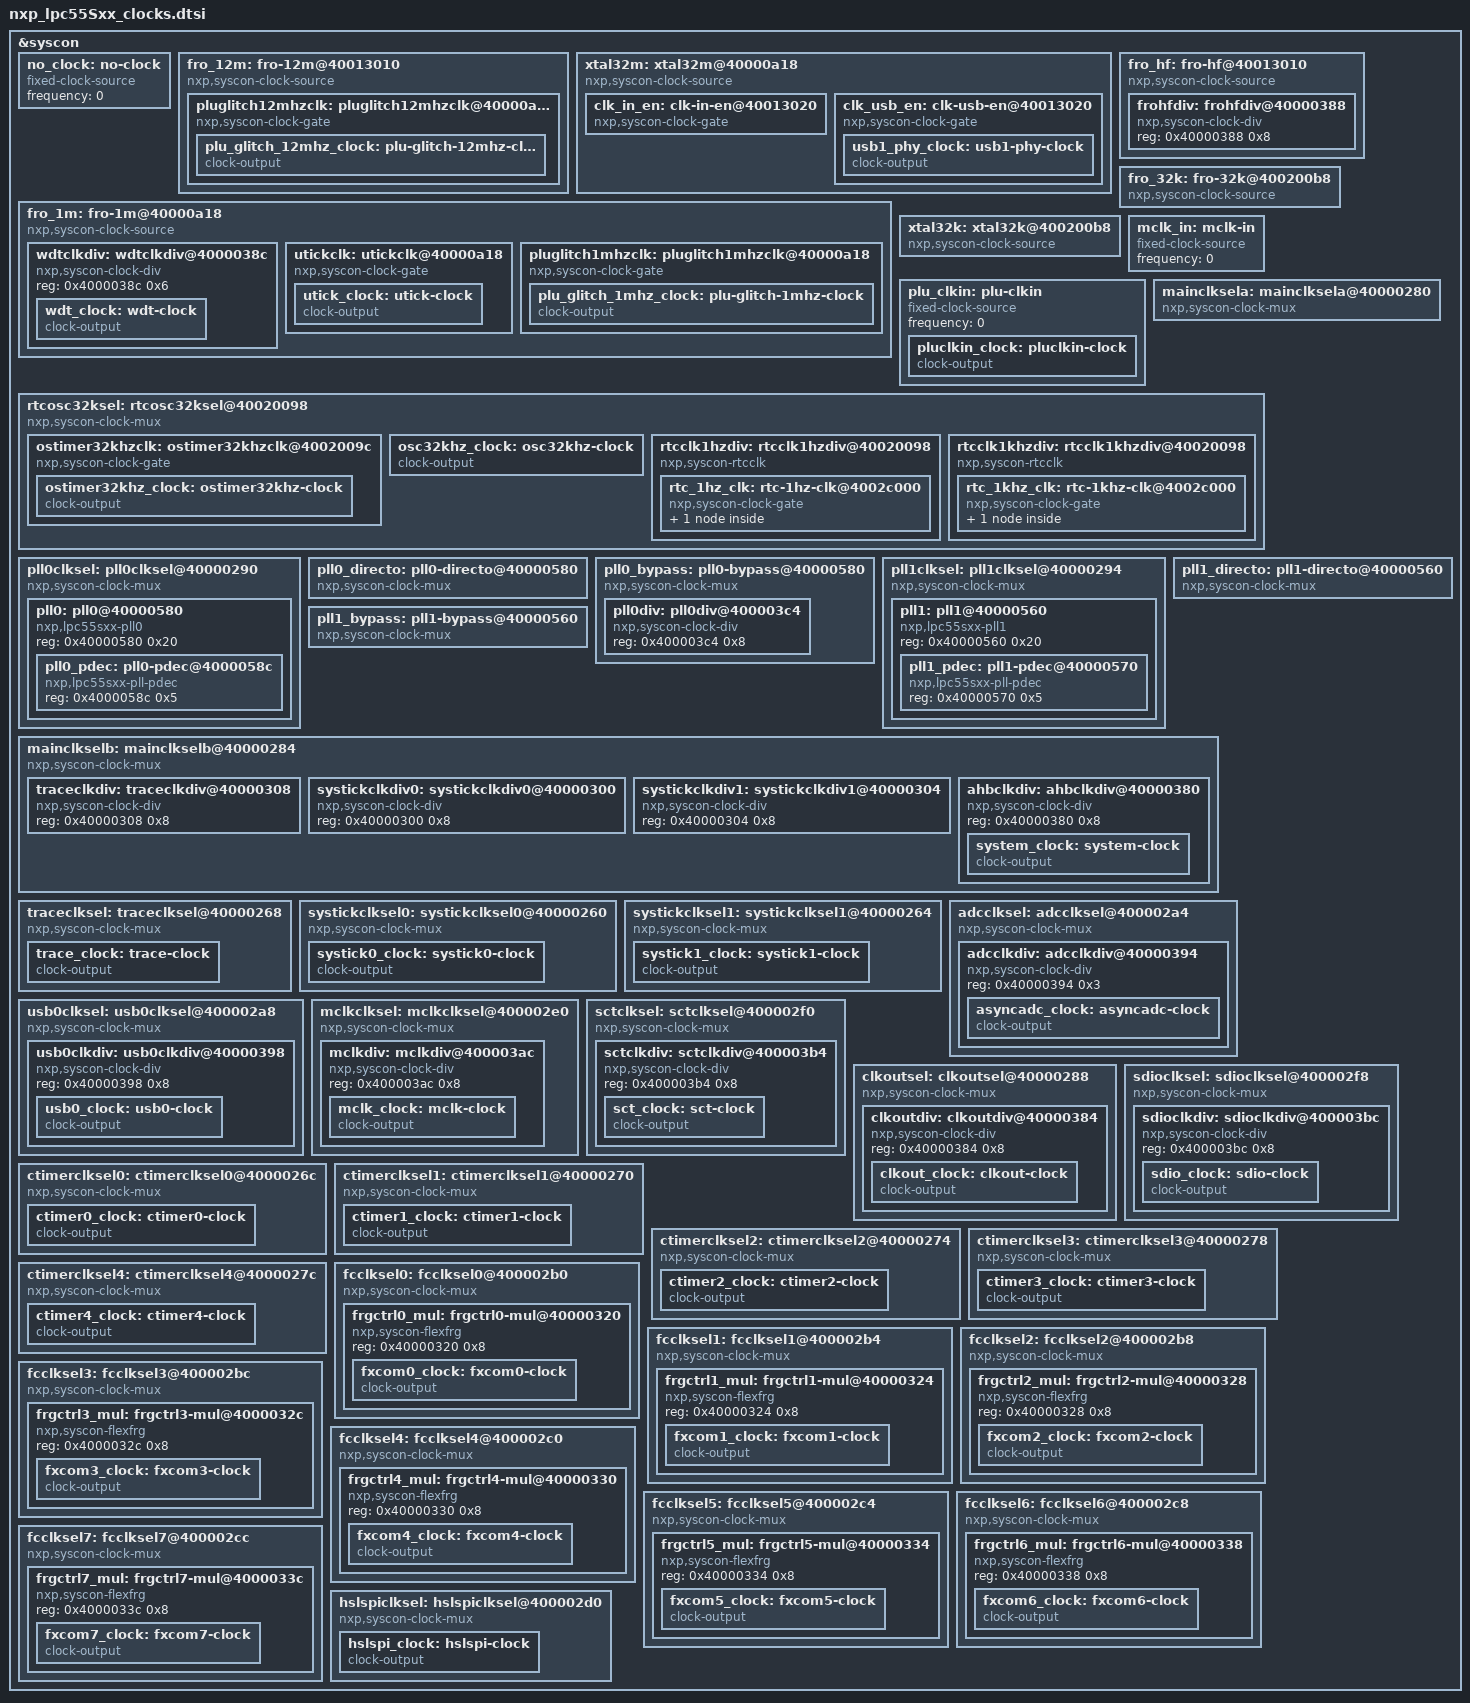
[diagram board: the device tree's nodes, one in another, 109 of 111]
/*
 * Copyright 2024 NXP
 *
 * SPDX-License-Identifier: Apache-2.0
 */

/* Generated from NXP MCUX clock data */
&syscon {
	#address-cells = <1>;
	#size-cells = <1>;

	/* Root clock sources */
	no_clock: no-clock {
		/* Dummy node- indicates no clock source was selected */
		compatible = "fixed-clock-source";
		#clock-cells = <0>;
		frequency = <0>;
	};

	fro_12m: fro-12m@40013010 {
		compatible = "nxp,syscon-clock-source";
		offset = <0xe>;
		#clock-cells = <1>;
		/* ANACTRL::FRO192M_CTRL[ENA_12MHZCLK] */
		reg = <0x40013010 0x1>;
		frequency = <12000000>;
		#address-cells = <1>;
		#size-cells = <1>;

		pluglitch12mhzclk: pluglitch12mhzclk@40000a18 {
			compatible = "nxp,syscon-clock-gate";
			#clock-cells = <1>;
			/* SYSCON::CLOCK_CTRL[PLU_DEGLITCH_CLK_ENA] */
			reg = <0x40000a18 0x1>;
			offset = <0x9>;

			plu_glitch_12mhz_clock: plu-glitch-12mhz-clock {
				compatible = "clock-output";
				#clock-cells = <1>;
			};
		};
	};

	xtal32m: xtal32m@40000a18 {
		compatible = "nxp,syscon-clock-source";
		offset = <0x5>;
		#clock-cells = <1>;
		/* PMC::PDRUNCFG0[PDEN_LDOXO32M | PDEN_XTAL32M] */
		pdown-mask = <0x100100>;
		/* SYSCON::CLOCK_CTRL[CLKIN_ENA] */
		reg = <0x40000a18 0x1>;
		/* External clock source (default 16 MHz) */
		frequency = <16000000>;
		#address-cells = <1>;
		#size-cells = <1>;

		clk_in_en: clk-in-en@40013020 {
			compatible = "nxp,syscon-clock-gate";
			#clock-cells = <1>;
			/* ANACTRL::XO32M_CTRL[ENABLE_SYSTEM_CLK_OUT] */
			reg = <0x40013020 0x1>;
			offset = <0x18>;
		};

		clk_usb_en: clk-usb-en@40013020 {
			compatible = "nxp,syscon-clock-gate";
			#clock-cells = <1>;
			/* ANACTRL::XO32M_CTRL[ENABLE_PLL_USB_OUT] */
			reg = <0x40013020 0x1>;
			offset = <0x17>;

			usb1_phy_clock: usb1-phy-clock {
				compatible = "clock-output";
				#clock-cells = <1>;
			};
		};
	};

	fro_1m: fro-1m@40000a18 {
		compatible = "nxp,syscon-clock-source";
		offset = <0x6>;
		#clock-cells = <1>;
		/* SYSCON::CLOCK_CTRL[FRO1MHZ_CLK_ENA] */
		reg = <0x40000a18 0x1>;
		frequency = <1000000>;
		#address-cells = <1>;
		#size-cells = <1>;

		wdtclkdiv: wdtclkdiv@4000038c {
			compatible = "nxp,syscon-clock-div";
			#clock-cells = <1>;
			/* SYSCON::WDTCLKDIV[DIV] */
			reg = <0x4000038c 0x6>;

			wdt_clock: wdt-clock {
				compatible = "clock-output";
				#clock-cells = <1>;
			};
		};

		utickclk: utickclk@40000a18 {
			compatible = "nxp,syscon-clock-gate";
			#clock-cells = <1>;
			/* SYSCON::CLOCK_CTRL[FRO1MHZ_UTICK_ENA] */
			reg = <0x40000a18 0x1>;
			offset = <0x2>;

			utick_clock: utick-clock {
				compatible = "clock-output";
				#clock-cells = <1>;
			};
		};

		pluglitch1mhzclk: pluglitch1mhzclk@40000a18 {
			compatible = "nxp,syscon-clock-gate";
			#clock-cells = <1>;
			/* SYSCON::CLOCK_CTRL[PLU_DEGLITCH_CLK_ENA] */
			reg = <0x40000a18 0x1>;
			offset = <0x9>;

			plu_glitch_1mhz_clock: plu-glitch-1mhz-clock {
				compatible = "clock-output";
				#clock-cells = <1>;
			};
		};
	};

	fro_hf: fro-hf@40013010 {
		compatible = "nxp,syscon-clock-source";
		offset = <0x1e>;
		#clock-cells = <1>;
		/* ANACTRL::FRO192M_CTRL[ENA_96MHZCLK] */
		reg = <0x40013010 0x1>;
		frequency = <96000000>;
		#address-cells = <1>;
		#size-cells = <1>;

		frohfdiv: frohfdiv@40000388 {
			compatible = "nxp,syscon-clock-div";
			#clock-cells = <1>;
			/* SYSCON::FROHFDIV[DIV] */
			reg = <0x40000388 0x8>;
		};
	};

	fro_32k: fro-32k@400200b8 {
		compatible = "nxp,syscon-clock-source";
		offset = <0x6>;
		#clock-cells = <1>;
		/* PMC::PDRUNCFG0[PDEN_FRO32K] */
		pdown-mask = <0x40>;
		/* PMC::PDRUNCFG0[PDEN_FRO32K] */
		reg = <0x400200b8 0x1>;
		frequency = <32768>;
	};

	xtal32k: xtal32k@400200b8 {
		compatible = "nxp,syscon-clock-source";
		offset = <0x7>;
		#clock-cells = <1>;
		/* PMC::PDRUNCFG0[PDEN_XTAL32K] */
		pdown-mask = <0x80>;
		/* PMC::PDRUNCFG0[PDEN_XTAL32K] */
		reg = <0x400200b8 0x1>;
		/* External clock source (default 32768 Hz) */
		frequency = <32768>;
	};

	mclk_in: mclk-in {
		compatible = "fixed-clock-source";
		#clock-cells = <0>;
		/* External clock source */
		frequency = <0>;
	};

	plu_clkin: plu-clkin {
		compatible = "fixed-clock-source";
		#clock-cells = <0>;
		/* External clock source */
		frequency = <0>;

		pluclkin_clock: pluclkin-clock {
			compatible = "clock-output";
			#clock-cells = <1>;
		};
	};

	/* Clock muxes */
	mainclksela: mainclksela@40000280 {
		compatible = "nxp,syscon-clock-mux";
		#clock-cells = <1>;
		/* SYSCON::MAINCLKSELA[SEL] */
		reg = <0x40000280 0x3>;
		offset = <0x0>;
		safe-mux;
		input-sources = <&fro_12m &clk_in_en &fro_1m &fro_hf>;
	};

	rtcosc32ksel: rtcosc32ksel@40020098 {
		compatible = "nxp,syscon-clock-mux";
		#clock-cells = <1>;
		/* PMC::RTCOSC32K[SEL] */
		reg = <0x40020098 0x1>;
		offset = <0x0>;
		input-sources = <&fro_32k &xtal32k>;
		#address-cells = <1>;
		#size-cells = <1>;

		ostimer32khzclk: ostimer32khzclk@4002009c {
			compatible = "nxp,syscon-clock-gate";
			#clock-cells = <1>;
			/* PMC::OSTIMER[CLOCKENABLE] */
			reg = <0x4002009c 0x1>;
			offset = <0x1>;

			ostimer32khz_clock: ostimer32khz-clock {
				compatible = "clock-output";
				#clock-cells = <1>;
			};
		};

		osc32khz_clock: osc32khz-clock {
			compatible = "clock-output";
			#clock-cells = <1>;
		};

		rtcclk1hzdiv: rtcclk1hzdiv@40020098 {
			compatible = "nxp,syscon-rtcclk";
			#clock-cells = <1>;
			/* PMC::RTCOSC32K[CLK1HZDIV] */
			reg = <0x40020098 0xb>;
			offset = <0x10>;
			add-factor = <31744>;
			#address-cells = <1>;
			#size-cells = <1>;

			rtc_1hz_clk: rtc-1hz-clk@4002c000 {
				compatible = "nxp,syscon-clock-gate";
				#clock-cells = <1>;
				/* RTC::CTRL[RTC_EN] */
				reg = <0x4002c000 0x1>;
				offset = <0x7>;

				rtc1hz_clock: rtc1hz-clock {
					compatible = "clock-output";
					#clock-cells = <1>;
				};
			};
		};

		rtcclk1khzdiv: rtcclk1khzdiv@40020098 {
			compatible = "nxp,syscon-rtcclk";
			#clock-cells = <1>;
			/* PMC::RTCOSC32K[CLK1KHZDIV] */
			reg = <0x40020098 0x3>;
			offset = <0x1>;
			add-factor = <28>;
			#address-cells = <1>;
			#size-cells = <1>;

			rtc_1khz_clk: rtc-1khz-clk@4002c000 {
				compatible = "nxp,syscon-clock-gate";
				#clock-cells = <1>;
				/* RTC::CTRL[RTC1KHZ_EN] */
				reg = <0x4002c000 0x1>;
				offset = <0x6>;

				rtc1khz_clock: rtc1khz-clock {
					compatible = "clock-output";
					#clock-cells = <1>;
				};
			};
		};
	};

	pll0clksel: pll0clksel@40000290 {
		compatible = "nxp,syscon-clock-mux";
		#clock-cells = <1>;
		/* SYSCON::PLL0CLKSEL[SEL] */
		reg = <0x40000290 0x3>;
		offset = <0x0>;
		input-sources = <&fro_12m &clk_in_en &fro_1m &rtcosc32ksel
				&no_clock>;
		#address-cells = <1>;
		#size-cells = <1>;

		pll0: pll0@40000580 {
			compatible = "nxp,lpc55sxx-pll0";
			reg = <0x40000580 0x20>;
			#clock-cells = <9>;
			#address-cells = <1>;
			#size-cells = <1>;

			pll0_pdec: pll0-pdec@4000058c {
				compatible = "nxp,lpc55sxx-pll-pdec";
				/* SYSCON::PLL0PDEC[PDIV] */
				reg = <0x4000058c 0x5>;
				#clock-cells = <1>;
			};
		};
	};

	pll0_directo: pll0-directo@40000580 {
		compatible = "nxp,syscon-clock-mux";
		#clock-cells = <1>;
		/* SYSCON::PLL0CTRL[BYPASSPOSTDIV] */
		reg = <0x40000580 0x1>;
		offset = <0x14>;
		input-sources = <&pll0_pdec &pll0>;
	};

	pll0_bypass: pll0-bypass@40000580 {
		compatible = "nxp,syscon-clock-mux";
		#clock-cells = <1>;
		/* SYSCON::PLL0CTRL[BYPASSPLL] */
		reg = <0x40000580 0x1>;
		offset = <0xf>;
		input-sources = <&pll0_directo &pll0clksel>;
		#address-cells = <1>;
		#size-cells = <1>;

		pll0div: pll0div@400003c4 {
			compatible = "nxp,syscon-clock-div";
			#clock-cells = <1>;
			/* SYSCON::PLL0CLKDIV[DIV] */
			reg = <0x400003c4 0x8>;
		};
	};

	pll1clksel: pll1clksel@40000294 {
		compatible = "nxp,syscon-clock-mux";
		#clock-cells = <1>;
		/* SYSCON::PLL1CLKSEL[SEL] */
		reg = <0x40000294 0x3>;
		offset = <0x0>;
		input-sources = <&fro_12m &clk_in_en &fro_1m &rtcosc32ksel
				&no_clock>;
		#address-cells = <1>;
		#size-cells = <1>;

		pll1: pll1@40000560 {
			compatible = "nxp,lpc55sxx-pll1";
			reg = <0x40000560 0x20>;
			#clock-cells = <6>;
			#address-cells = <1>;
			#size-cells = <1>;

			pll1_pdec: pll1-pdec@40000570 {
				compatible = "nxp,lpc55sxx-pll-pdec";
				/* SYSCON::PLL1PDEC[PDIV] */
				reg = <0x40000570 0x5>;
				#clock-cells = <1>;
			};
		};
	};

	pll1_directo: pll1-directo@40000560 {
		compatible = "nxp,syscon-clock-mux";
		#clock-cells = <1>;
		/* SYSCON::PLL1CTRL[BYPASSPOSTDIV] */
		reg = <0x40000560 0x1>;
		offset = <0x14>;
		input-sources = <&pll1_pdec &pll1>;
	};

	pll1_bypass: pll1-bypass@40000560 {
		compatible = "nxp,syscon-clock-mux";
		#clock-cells = <1>;
		/* SYSCON::PLL1CTRL[BYPASSPLL] */
		reg = <0x40000560 0x1>;
		offset = <0xf>;
		input-sources = <&pll1_directo &pll1clksel>;
	};

	mainclkselb: mainclkselb@40000284 {
		compatible = "nxp,syscon-clock-mux";
		#clock-cells = <1>;
		/* SYSCON::MAINCLKSELB[SEL] */
		reg = <0x40000284 0x3>;
		offset = <0x0>;
		safe-mux;
		input-sources = <&mainclksela &pll0_bypass &pll1_bypass &rtcosc32ksel>;
		#address-cells = <1>;
		#size-cells = <1>;

		traceclkdiv: traceclkdiv@40000308 {
			compatible = "nxp,syscon-clock-div";
			#clock-cells = <1>;
			/* SYSCON::TRACECLKDIV[DIV] */
			reg = <0x40000308 0x8>;
		};

		systickclkdiv0: systickclkdiv0@40000300 {
			compatible = "nxp,syscon-clock-div";
			#clock-cells = <1>;
			/* SYSCON::SYSTICKCLKDIV0[DIV] */
			reg = <0x40000300 0x8>;
		};

		systickclkdiv1: systickclkdiv1@40000304 {
			compatible = "nxp,syscon-clock-div";
			#clock-cells = <1>;
			/* SYSCON::SYSTICKCLKDIV1[DIV] */
			reg = <0x40000304 0x8>;
		};

		ahbclkdiv: ahbclkdiv@40000380 {
			compatible = "nxp,syscon-clock-div";
			#clock-cells = <1>;
			/* SYSCON::AHBCLKDIV[DIV] */
			reg = <0x40000380 0x8>;

			system_clock: system-clock {
				compatible = "clock-output";
				#clock-cells = <1>;
			};
		};
	};

	traceclksel: traceclksel@40000268 {
		compatible = "nxp,syscon-clock-mux";
		#clock-cells = <1>;
		/* SYSCON::TRACECLKSEL[SEL] */
		reg = <0x40000268 0x3>;
		offset = <0x0>;
		input-sources = <&traceclkdiv &fro_1m &rtcosc32ksel &no_clock>;

		trace_clock: trace-clock {
			compatible = "clock-output";
			#clock-cells = <1>;
		};
	};

	systickclksel0: systickclksel0@40000260 {
		compatible = "nxp,syscon-clock-mux";
		#clock-cells = <1>;
		/* SYSCON::SYSTICKCLKSEL0[SEL] */
		reg = <0x40000260 0x3>;
		offset = <0x0>;
		input-sources = <&systickclkdiv0 &fro_1m &rtcosc32ksel &no_clock>;

		systick0_clock: systick0-clock {
			compatible = "clock-output";
			#clock-cells = <1>;
		};
	};

	systickclksel1: systickclksel1@40000264 {
		compatible = "nxp,syscon-clock-mux";
		#clock-cells = <1>;
		/* SYSCON::SYSTICKCLKSEL1[SEL] */
		reg = <0x40000264 0x3>;
		offset = <0x0>;
		input-sources = <&systickclkdiv1 &fro_1m &rtcosc32ksel &no_clock>;

		systick1_clock: systick1-clock {
			compatible = "clock-output";
			#clock-cells = <1>;
		};
	};

	adcclksel: adcclksel@400002a4 {
		compatible = "nxp,syscon-clock-mux";
		#clock-cells = <1>;
		/* SYSCON::ADCCLKSEL[SEL] */
		reg = <0x400002a4 0x3>;
		offset = <0x0>;
		input-sources = <&mainclkselb &pll0_bypass &fro_hf &no_clock>;
		#address-cells = <1>;
		#size-cells = <1>;

		adcclkdiv: adcclkdiv@40000394 {
			compatible = "nxp,syscon-clock-div";
			#clock-cells = <1>;
			/* SYSCON::ADCCLKDIV[DIV] */
			reg = <0x40000394 0x3>;

			asyncadc_clock: asyncadc-clock {
				compatible = "clock-output";
				#clock-cells = <1>;
			};
		};
	};

	usb0clksel: usb0clksel@400002a8 {
		compatible = "nxp,syscon-clock-mux";
		#clock-cells = <1>;
		/* SYSCON::USB0CLKSEL[SEL] */
		reg = <0x400002a8 0x3>;
		offset = <0x0>;
		input-sources = <&mainclkselb &pll0_bypass &no_clock &fro_hf
				&no_clock &pll1_bypass &no_clock>;
		#address-cells = <1>;
		#size-cells = <1>;

		usb0clkdiv: usb0clkdiv@40000398 {
			compatible = "nxp,syscon-clock-div";
			#clock-cells = <1>;
			/* SYSCON::USB0CLKDIV[DIV] */
			reg = <0x40000398 0x8>;

			usb0_clock: usb0-clock {
				compatible = "clock-output";
				#clock-cells = <1>;
			};
		};
	};

	mclkclksel: mclkclksel@400002e0 {
		compatible = "nxp,syscon-clock-mux";
		#clock-cells = <1>;
		/* SYSCON::MCLKCLKSEL[SEL] */
		reg = <0x400002e0 0x3>;
		offset = <0x0>;
		input-sources = <&fro_hf &pll0_bypass &no_clock>;
		#address-cells = <1>;
		#size-cells = <1>;

		mclkdiv: mclkdiv@400003ac {
			compatible = "nxp,syscon-clock-div";
			#clock-cells = <1>;
			/* SYSCON::MCLKDIV[DIV] */
			reg = <0x400003ac 0x8>;

			mclk_clock: mclk-clock {
				compatible = "clock-output";
				#clock-cells = <1>;
			};
		};
	};

	sctclksel: sctclksel@400002f0 {
		compatible = "nxp,syscon-clock-mux";
		#clock-cells = <1>;
		/* SYSCON::SCTCLKSEL[SEL] */
		reg = <0x400002f0 0x3>;
		offset = <0x0>;
		input-sources = <&mainclkselb &pll0_bypass &clk_in_en &fro_hf
				&no_clock &mclk_in &no_clock>;
		#address-cells = <1>;
		#size-cells = <1>;

		sctclkdiv: sctclkdiv@400003b4 {
			compatible = "nxp,syscon-clock-div";
			#clock-cells = <1>;
			/* SYSCON::SCTCLKDIV[DIV] */
			reg = <0x400003b4 0x8>;

			sct_clock: sct-clock {
				compatible = "clock-output";
				#clock-cells = <1>;
			};
		};
	};

	clkoutsel: clkoutsel@40000288 {
		compatible = "nxp,syscon-clock-mux";
		#clock-cells = <1>;
		/* SYSCON::CLKOUTSEL[SEL] */
		reg = <0x40000288 0x3>;
		offset = <0x0>;
		input-sources = <&mainclkselb &pll0_bypass &clk_in_en &fro_hf
				&fro_1m &pll1_bypass &rtcosc32ksel &no_clock>;
		#address-cells = <1>;
		#size-cells = <1>;

		clkoutdiv: clkoutdiv@40000384 {
			compatible = "nxp,syscon-clock-div";
			#clock-cells = <1>;
			/* SYSCON::CLKOUTDIV[DIV] */
			reg = <0x40000384 0x8>;

			clkout_clock: clkout-clock {
				compatible = "clock-output";
				#clock-cells = <1>;
			};
		};
	};

	sdioclksel: sdioclksel@400002f8 {
		compatible = "nxp,syscon-clock-mux";
		#clock-cells = <1>;
		/* SYSCON::SDIOCLKSEL[SEL] */
		reg = <0x400002f8 0x3>;
		offset = <0x0>;
		input-sources = <&mainclkselb &pll0_bypass &no_clock &fro_hf
				&no_clock &pll1_bypass &no_clock>;
		#address-cells = <1>;
		#size-cells = <1>;

		sdioclkdiv: sdioclkdiv@400003bc {
			compatible = "nxp,syscon-clock-div";
			#clock-cells = <1>;
			/* SYSCON::SDIOCLKDIV[DIV] */
			reg = <0x400003bc 0x8>;

			sdio_clock: sdio-clock {
				compatible = "clock-output";
				#clock-cells = <1>;
			};
		};
	};

	ctimerclksel0: ctimerclksel0@4000026c {
		compatible = "nxp,syscon-clock-mux";
		#clock-cells = <1>;
		/* SYSCON::CTIMERCLKSEL0[SEL] */
		reg = <0x4000026c 0x3>;
		offset = <0x0>;
		input-sources = <&mainclkselb &pll0_bypass &no_clock &fro_hf
				&fro_1m &mclk_in &rtcosc32ksel &no_clock>;

		ctimer0_clock: ctimer0-clock {
			compatible = "clock-output";
			#clock-cells = <1>;
		};
	};

	ctimerclksel1: ctimerclksel1@40000270 {
		compatible = "nxp,syscon-clock-mux";
		#clock-cells = <1>;
		/* SYSCON::CTIMERCLKSEL1[SEL] */
		reg = <0x40000270 0x3>;
		offset = <0x0>;
		input-sources = <&mainclkselb &pll0_bypass &no_clock &fro_hf
				&fro_1m &mclk_in &rtcosc32ksel &no_clock>;

		ctimer1_clock: ctimer1-clock {
			compatible = "clock-output";
			#clock-cells = <1>;
		};
	};

	ctimerclksel2: ctimerclksel2@40000274 {
		compatible = "nxp,syscon-clock-mux";
		#clock-cells = <1>;
		/* SYSCON::CTIMERCLKSEL2[SEL] */
		reg = <0x40000274 0x3>;
		offset = <0x0>;
		input-sources = <&mainclkselb &pll0_bypass &no_clock &fro_hf
				&fro_1m &mclk_in &rtcosc32ksel &no_clock>;

		ctimer2_clock: ctimer2-clock {
			compatible = "clock-output";
			#clock-cells = <1>;
		};
	};

	ctimerclksel3: ctimerclksel3@40000278 {
		compatible = "nxp,syscon-clock-mux";
		#clock-cells = <1>;
		/* SYSCON::CTIMERCLKSEL3[SEL] */
		reg = <0x40000278 0x3>;
		offset = <0x0>;
		input-sources = <&mainclkselb &pll0_bypass &no_clock &fro_hf
				&fro_1m &mclk_in &rtcosc32ksel &no_clock>;

		ctimer3_clock: ctimer3-clock {
			compatible = "clock-output";
			#clock-cells = <1>;
		};
	};

	ctimerclksel4: ctimerclksel4@4000027c {
		compatible = "nxp,syscon-clock-mux";
		#clock-cells = <1>;
		/* SYSCON::CTIMERCLKSEL4[SEL] */
		reg = <0x4000027c 0x3>;
		offset = <0x0>;
		input-sources = <&mainclkselb &pll0_bypass &no_clock &fro_hf
				&fro_1m &mclk_in &rtcosc32ksel &no_clock>;

		ctimer4_clock: ctimer4-clock {
			compatible = "clock-output";
			#clock-cells = <1>;
		};
	};

	fcclksel0: fcclksel0@400002b0 {
		compatible = "nxp,syscon-clock-mux";
		#clock-cells = <1>;
		/* SYSCON::FCCLKSEL0[SEL] */
		reg = <0x400002b0 0x3>;
		offset = <0x0>;
		input-sources = <&mainclkselb &pll0div &fro_12m &frohfdiv &fro_1m
				&mclk_in &rtcosc32ksel &no_clock>;
		#address-cells = <1>;
		#size-cells = <1>;

		frgctrl0_mul: frgctrl0-mul@40000320 {
			compatible = "nxp,syscon-flexfrg";
			#clock-cells = <1>;
			/* SYSCON::FLEXFRG0CTRL[MULT] */
			reg = <0x40000320 0x8>;

			fxcom0_clock: fxcom0-clock {
				compatible = "clock-output";
				#clock-cells = <1>;
			};
		};
	};

	fcclksel1: fcclksel1@400002b4 {
		compatible = "nxp,syscon-clock-mux";
		#clock-cells = <1>;
		/* SYSCON::FCCLKSEL1[SEL] */
		reg = <0x400002b4 0x3>;
		offset = <0x0>;
		input-sources = <&mainclkselb &pll0div &fro_12m &frohfdiv &fro_1m
				&mclk_in &rtcosc32ksel &no_clock>;
		#address-cells = <1>;
		#size-cells = <1>;

		frgctrl1_mul: frgctrl1-mul@40000324 {
			compatible = "nxp,syscon-flexfrg";
			#clock-cells = <1>;
			/* SYSCON::FLEXFRG1CTRL[MULT] */
			reg = <0x40000324 0x8>;

			fxcom1_clock: fxcom1-clock {
				compatible = "clock-output";
				#clock-cells = <1>;
			};
		};
	};

	fcclksel2: fcclksel2@400002b8 {
		compatible = "nxp,syscon-clock-mux";
		#clock-cells = <1>;
		/* SYSCON::FCCLKSEL2[SEL] */
		reg = <0x400002b8 0x3>;
		offset = <0x0>;
		input-sources = <&mainclkselb &pll0div &fro_12m &frohfdiv &fro_1m
				&mclk_in &rtcosc32ksel &no_clock>;
		#address-cells = <1>;
		#size-cells = <1>;

		frgctrl2_mul: frgctrl2-mul@40000328 {
			compatible = "nxp,syscon-flexfrg";
			#clock-cells = <1>;
			/* SYSCON::FLEXFRG2CTRL[MULT] */
			reg = <0x40000328 0x8>;

			fxcom2_clock: fxcom2-clock {
				compatible = "clock-output";
				#clock-cells = <1>;
			};
		};
	};

	fcclksel3: fcclksel3@400002bc {
		compatible = "nxp,syscon-clock-mux";
		#clock-cells = <1>;
		/* SYSCON::FCCLKSEL3[SEL] */
		reg = <0x400002bc 0x3>;
		offset = <0x0>;
		input-sources = <&mainclkselb &pll0div &fro_12m &frohfdiv &fro_1m
				&mclk_in &rtcosc32ksel &no_clock>;
		#address-cells = <1>;
		#size-cells = <1>;

		frgctrl3_mul: frgctrl3-mul@4000032c {
			compatible = "nxp,syscon-flexfrg";
			#clock-cells = <1>;
			/* SYSCON::FLEXFRG3CTRL[MULT] */
			reg = <0x4000032c 0x8>;

			fxcom3_clock: fxcom3-clock {
				compatible = "clock-output";
				#clock-cells = <1>;
			};
		};
	};

	fcclksel4: fcclksel4@400002c0 {
		compatible = "nxp,syscon-clock-mux";
		#clock-cells = <1>;
		/* SYSCON::FCCLKSEL4[SEL] */
		reg = <0x400002c0 0x3>;
		offset = <0x0>;
		input-sources = <&mainclkselb &pll0div &fro_12m &frohfdiv &fro_1m
				&mclk_in &rtcosc32ksel &no_clock>;
		#address-cells = <1>;
		#size-cells = <1>;

		frgctrl4_mul: frgctrl4-mul@40000330 {
			compatible = "nxp,syscon-flexfrg";
			#clock-cells = <1>;
			/* SYSCON::FLEXFRG4CTRL[MULT] */
			reg = <0x40000330 0x8>;

			fxcom4_clock: fxcom4-clock {
				compatible = "clock-output";
				#clock-cells = <1>;
			};
		};
	};

	fcclksel5: fcclksel5@400002c4 {
		compatible = "nxp,syscon-clock-mux";
		#clock-cells = <1>;
		/* SYSCON::FCCLKSEL5[SEL] */
		reg = <0x400002c4 0x3>;
		offset = <0x0>;
		input-sources = <&mainclkselb &pll0div &fro_12m &frohfdiv &fro_1m
				&mclk_in &rtcosc32ksel &no_clock>;
		#address-cells = <1>;
		#size-cells = <1>;

		frgctrl5_mul: frgctrl5-mul@40000334 {
			compatible = "nxp,syscon-flexfrg";
			#clock-cells = <1>;
			/* SYSCON::FLEXFRG5CTRL[MULT] */
			reg = <0x40000334 0x8>;

			fxcom5_clock: fxcom5-clock {
				compatible = "clock-output";
				#clock-cells = <1>;
			};
		};
	};

	fcclksel6: fcclksel6@400002c8 {
		compatible = "nxp,syscon-clock-mux";
		#clock-cells = <1>;
		/* SYSCON::FCCLKSEL6[SEL] */
		reg = <0x400002c8 0x3>;
		offset = <0x0>;
		input-sources = <&mainclkselb &pll0div &fro_12m &frohfdiv &fro_1m
				&mclk_in &rtcosc32ksel &no_clock>;
		#address-cells = <1>;
		#size-cells = <1>;

		frgctrl6_mul: frgctrl6-mul@40000338 {
			compatible = "nxp,syscon-flexfrg";
			#clock-cells = <1>;
			/* SYSCON::FLEXFRG6CTRL[MULT] */
			reg = <0x40000338 0x8>;

			fxcom6_clock: fxcom6-clock {
				compatible = "clock-output";
				#clock-cells = <1>;
			};
		};
	};

	fcclksel7: fcclksel7@400002cc {
		compatible = "nxp,syscon-clock-mux";
		#clock-cells = <1>;
		/* SYSCON::FCCLKSEL7[SEL] */
		reg = <0x400002cc 0x3>;
		offset = <0x0>;
		input-sources = <&mainclkselb &pll0div &fro_12m &frohfdiv &fro_1m
				&mclk_in &rtcosc32ksel &no_clock>;
		#address-cells = <1>;
		#size-cells = <1>;

		frgctrl7_mul: frgctrl7-mul@4000033c {
			compatible = "nxp,syscon-flexfrg";
			#clock-cells = <1>;
			/* SYSCON::FLEXFRG7CTRL[MULT] */
			reg = <0x4000033c 0x8>;

			fxcom7_clock: fxcom7-clock {
				compatible = "clock-output";
				#clock-cells = <1>;
			};
		};
	};

	hslspiclksel: hslspiclksel@400002d0 {
		compatible = "nxp,syscon-clock-mux";
		#clock-cells = <1>;
		/* SYSCON::HSLSPICLKSEL[SEL] */
		reg = <0x400002d0 0x3>;
		offset = <0x0>;
		input-sources = <&mainclkselb &pll0div &fro_12m &frohfdiv &fro_1m
				&no_clock &rtcosc32ksel &no_clock>;

		hslspi_clock: hslspi-clock {
			compatible = "clock-output";
			#clock-cells = <1>;
		};
	};
};
